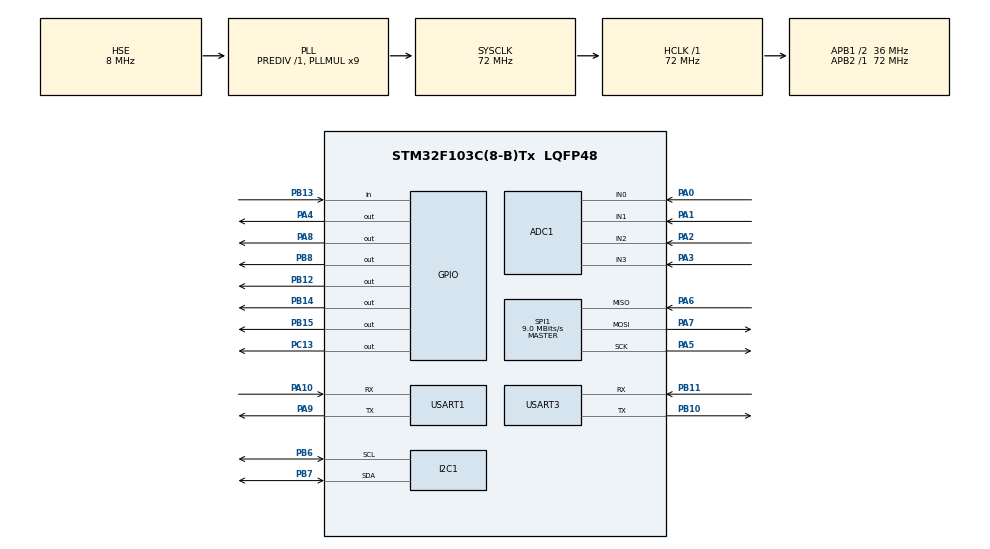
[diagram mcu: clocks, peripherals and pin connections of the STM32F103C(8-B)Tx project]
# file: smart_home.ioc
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ADC1.Channel-8\#ChannelRegularConversion=ADC_CHANNEL_0
ADC1.ContinuousConvMode=DISABLE
ADC1.EnableRegularConversion=ENABLE
ADC1.NbrOfConversion=1
ADC1.NbrOfConversionFlag=1
ADC1.Rank-8\#ChannelRegularConversion=1
ADC1.SamplingTime-8\#ChannelRegularConversion=ADC_SAMPLETIME_239CYCLES_5
ADC1.master=1
Dma.Request0=USART3_TX
Dma.USART3_TX.0.Direction=DMA_MEMORY_TO_PERIPH
Dma.USART3_TX.0.Instance=DMA1_Channel2
Dma.USART3_TX.0.MemDataAlignment=DMA_MDATAALIGN_BYTE
Dma.USART3_TX.0.MemInc=DMA_MINC_ENABLE
Dma.USART3_TX.0.Mode=DMA_NORMAL
Dma.USART3_TX.0.PeriphDataAlignment=DMA_PDATAALIGN_BYTE
Dma.USART3_TX.0.PeriphInc=DMA_PINC_DISABLE
Dma.USART3_TX.0.Priority=DMA_PRIORITY_LOW
I2C1.I2C_Mode=I2C_Fast
Mcu.Family=STM32F1
Mcu.Name=STM32F103C(8-B)Tx
Mcu.Package=LQFP48
NVIC.DMA1_Channel2_IRQn=true\:0\:0\:false\:false\:true\:false\:true\:true
NVIC.PriorityGroup=NVIC_PRIORITYGROUP_4
NVIC.USART3_IRQn=true\:5\:0\:true\:false\:true\:true\:true\:true
PA0-WKUP.Signal=ADCx_IN0
PA1.Signal=ADCx_IN1
PA10.Mode=Asynchronous
PA10.Signal=USART1_RX
PA13.Mode=Serial_Wire
PA13.Signal=SYS_JTMS-SWDIO
PA14.Mode=Serial_Wire
PA14.Signal=SYS_JTCK-SWCLK
PA2.Signal=ADCx_IN2
PA3.Signal=ADCx_IN3
PA4.GPIO_ModeDefaultOutputPP=GPIO_MODE_OUTPUT_PP
PA4.GPIO_PuPd=GPIO_PULLUP
PA4.GPIO_Speed=GPIO_SPEED_FREQ_HIGH
PA4.PinState=GPIO_PIN_SET
PA4.Signal=GPIO_Output
PA5.Mode=Full_Duplex_Master
PA5.Signal=SPI1_SCK
PA6.Mode=Full_Duplex_Master
PA6.Signal=SPI1_MISO
PA7.Mode=Full_Duplex_Master
PA7.Signal=SPI1_MOSI
PA8.GPIO_ModeDefaultOutputPP=GPIO_MODE_OUTPUT_OD
PA8.GPIO_PuPd=GPIO_PULLUP
PA8.GPIO_Speed=GPIO_SPEED_FREQ_HIGH
PA8.PinState=GPIO_PIN_RESET
PA8.Signal=GPIO_Output
PA9.Mode=Asynchronous
PA9.Signal=USART1_TX
PB10.Mode=Asynchronous
PB10.Signal=USART3_TX
PB11.Mode=Asynchronous
PB11.Signal=USART3_RX
PB12.Signal=GPIO_Output
PB13.GPIO_PuPd=GPIO_PULLDOWN
PB13.Signal=GPIO_Input
PB14.GPIO_ModeDefaultOutputPP=GPIO_MODE_OUTPUT_PP
PB14.GPIO_PuPd=GPIO_NOPULL
PB14.Signal=GPIO_Output
PB15.Signal=GPIO_Output
PB6.Mode=I2C
PB6.Signal=I2C1_SCL
PB7.Mode=I2C
PB7.Signal=I2C1_SDA
PB8.Signal=GPIO_Output
PC13-TAMPER-RTC.Signal=GPIO_Output
PD0-OSC_IN.Mode=HSE-External-Oscillator
PD0-OSC_IN.Signal=RCC_OSC_IN
PD1-OSC_OUT.Mode=HSE-External-Oscillator
PD1-OSC_OUT.Signal=RCC_OSC_OUT
ProjectManager.HeapSize=0x200
ProjectManager.StackSize=0x400
ProjectManager.TargetToolchain=CMake
RCC.ADCPresc=RCC_ADCPCLK2_DIV6
RCC.AHBFreq_Value=72000000
RCC.APB1CLKDivider=RCC_HCLK_DIV2
RCC.APB1Freq_Value=36000000
RCC.APB1TimFreq_Value=72000000
RCC.APB2Freq_Value=72000000
RCC.APB2TimFreq_Value=72000000
RCC.HCLKFreq_Value=72000000
RCC.PLLMUL=RCC_PLL_MUL9
RCC.PLLSourceVirtual=RCC_PLLSOURCE_HSE
RCC.SYSCLKFreq_VALUE=72000000
RCC.SYSCLKSource=RCC_SYSCLKSOURCE_PLLCLK
RCC.USBFreq_Value=72000000
SH.ADCx_IN0.0=ADC1_IN0,IN0
SH.ADCx_IN1.0=ADC1_IN1,IN1
SH.ADCx_IN2.0=ADC1_IN2,IN2
SH.ADCx_IN3.0=ADC1_IN3,IN3
SPI1.BaudRatePrescaler=SPI_BAUDRATEPRESCALER_8
SPI1.CalculateBaudRate=9.0 MBits/s
SPI1.Direction=SPI_DIRECTION_2LINES
SPI1.Mode=SPI_MODE_MASTER
SPI1.VirtualType=VM_MASTER
USART1.VirtualMode=VM_ASYNC
USART3.VirtualMode=VM_ASYNC
VP_IWDG_VS_IWDG.Mode=IWDG_Activate
VP_TIM4_VS_ClockSourceINT.Mode=Internal
board=custom

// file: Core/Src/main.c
/* USER CODE BEGIN Header */
/**
  ******************************************************************************
  * @file           : main.c
  * @brief          : Main program body
  ******************************************************************************
  * @attention
  *
  * Copyright (c) 2026 STMicroelectronics.
  * All rights reserved.
  *
  * This software is licensed under terms that can be found in the LICENSE file
  * in the root directory of this software component.
  * If no LICENSE file comes with this software, it is provided AS-IS.
  *
  ******************************************************************************
  */
/* USER CODE END Header */
#include "main.h"
#include "adc.h"
#include "dma.h"
#include "i2c.h"
#include "iwdg.h"
#include "spi.h"
#include "tim.h"
#include "usart.h"
#include "gpio.h"

/* USER CODE BEGIN Includes */
#include "retarget.h"
#include "app_scheduler.h"
/* USER CODE END Includes */

void SystemClock_Config(void);

int main(void)
{

  /* USER CODE BEGIN 1 */
  /* 阶段 8（F103 IAP）：app 链接在 0x08002000，必须在本函数内、HAL_Init 使能
   * SysTick 中断之前把向量表重映射到 app 基址，否则中断会跳回 0x08000000
   * 的 bootloader 向量表。 */
  SCB->VTOR = 0x08002000UL;
  __DSB();
  __ISB();
  /* 从 bootloader 跳转过来时 PRIMASK 可能仍为 1；app 按复位后的默认状态
   * 运行（中断开启），否则 HAL_Delay/HAL_GetTick 会永远等不到 SysTick。 */
  __set_PRIMASK(0);
  g_app_boot_stage = 1;
  /* USER CODE END 1 */

  /* MCU Configuration--------------------------------------------------------*/

  /* Reset of all peripherals, Initializes the Flash interface and the Systick. */
  HAL_Init();
  g_app_boot_stage = 2;

#ifdef APP_TEST_BAD_IMAGE
  /* 阶段 8 回滚验收专用（CMake 选项 APP_TEST_BAD_IMAGE，默认 OFF）：
   * 镜像向量与 CRC 均合法，但启动后立即死循环且不初始化/喂 IWDG，
   * 让 bootloader 启动时开启的 8s 看门狗反复复位（TESTING 次数用尽后回滚）。
   * 只允许出现在验收镜像中，正式固件不得开启此选项。 */
  while (1) {
  }
#endif

  /* Configure the system clock */
  SystemClock_Config();
  g_app_boot_stage = 3;

  /* Initialize all configured peripherals */
  MX_GPIO_Init();
  g_app_boot_stage = 4;
  MX_DMA_Init();
  g_app_boot_stage = 5;
  MX_I2C1_Init();
  g_app_boot_stage = 6;
  MX_USART1_UART_Init();
  g_app_boot_stage = 7;
  MX_ADC1_Init();
  g_app_boot_stage = 8;
  MX_SPI1_Init();
  g_app_boot_stage = 9;
  MX_USART3_UART_Init();
  g_app_boot_stage = 10;
  /* MX_IWDG_Init() 刻意不调用（阶段 1 验收整改 §3.1）：
   * CubeMX 生成的它有固定的 PR=4 / RLR=4095，窗口只有约 410ms（LSI 取下限时 273ms），
   * 而把超时改成 2s 的 BSP_IWDG_Init(2000) 要到 App_Scheduler_Init() 里才执行 ——
   * 中间夹着 OLED/EEPROM/BMP280 初始化，最坏情况会超过 410ms 被误复位。
   * 看门狗现在统一由 BSP_IWDG_Init() 在所有外设就绪后启动，且初始化全程按步喂狗。 */
  /* MX_IWDG_Init(); */
  MX_TIM4_Init();
  /* USER CODE BEGIN 2 */

  RetargetInit(&huart3);

  g_app_boot_stage = 11;
  App_Scheduler_Init();

  /* USER CODE END 2 */

  /* Infinite loop */
  /* USER CODE BEGIN WHILE */
  while (1)
  {
      App_Scheduler_Run();
    /* USER CODE END WHILE */

  }
}

void SystemClock_Config(void)
{
  RCC_OscInitTypeDef RCC_OscInitStruct = {0};
  RCC_ClkInitTypeDef RCC_ClkInitStruct = {0};
  RCC_PeriphCLKInitTypeDef PeriphClkInit = {0};

  /** Initializes the RCC Oscillators according to the specified parameters
  * in the RCC_OscInitTypeDef structure.
  */
  RCC_OscInitStruct.OscillatorType = RCC_OSCILLATORTYPE_LSI|RCC_OSCILLATORTYPE_HSE;
  RCC_OscInitStruct.HSEState = RCC_HSE_ON;
  RCC_OscInitStruct.HSEPredivValue = RCC_HSE_PREDIV_DIV1;
  RCC_OscInitStruct.HSIState = RCC_HSI_ON;
  RCC_OscInitStruct.LSIState = RCC_LSI_ON;
  RCC_OscInitStruct.PLL.PLLState = RCC_PLL_ON;
  RCC_OscInitStruct.PLL.PLLSource = RCC_PLLSOURCE_HSE;
  RCC_OscInitStruct.PLL.PLLMUL = RCC_PLL_MUL9;
  if (HAL_RCC_OscConfig(&RCC_OscInitStruct) != HAL_OK)
  {
    Error_Handler();
  }

  /** Initializes the CPU, AHB and APB buses clocks
  */
  RCC_ClkInitStruct.ClockType = RCC_CLOCKTYPE_HCLK|RCC_CLOCKTYPE_SYSCLK
                              |RCC_CLOCKTYPE_PCLK1|RCC_CLOCKTYPE_PCLK2;
  RCC_ClkInitStruct.SYSCLKSource = RCC_SYSCLKSOURCE_PLLCLK;
  RCC_ClkInitStruct.AHBCLKDivider = RCC_SYSCLK_DIV1;
  RCC_ClkInitStruct.APB1CLKDivider = RCC_HCLK_DIV2;
  RCC_ClkInitStruct.APB2CLKDivider = RCC_HCLK_DIV1;

  if (HAL_RCC_ClockConfig(&RCC_ClkInitStruct, FLASH_LATENCY_2) != HAL_OK)
  {
    Error_Handler();
  }
  PeriphClkInit.PeriphClockSelection = RCC_PERIPHCLK_ADC;
  PeriphClkInit.AdcClockSelection = RCC_ADCPCLK2_DIV6;
  if (HAL_RCCEx_PeriphCLKConfig(&PeriphClkInit) != HAL_OK)
  {
    Error_Handler();
  }
}

void Error_Handler(void)
{
  __disable_irq();
  while (1)
  {
  }
}
